VERSION "ev-fleet traction-motor 1.0"

NS_ :

BS_:

BU_: MotorFront MotorRear VCU

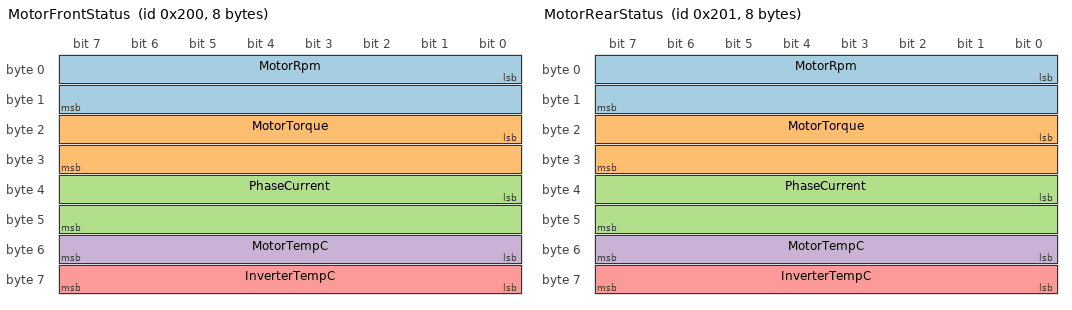
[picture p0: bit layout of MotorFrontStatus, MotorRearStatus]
BO_ 512 MotorFrontStatus: 8 MotorFront
 SG_ MotorRpm : 0|16@1- (1,0) [-32768|32767] "rpm" VCU
 SG_ MotorTorque : 16|16@1- (0.1,0) [-3276.8|3276.7] "Nm" VCU
 SG_ PhaseCurrent : 32|16@1- (0.1,0) [-3276.8|3276.7] "A" VCU
 SG_ MotorTempC : 48|8@1- (1,-40) [-40|87] "degC" VCU
 SG_ InverterTempC : 56|8@1- (1,-40) [-40|87] "degC" VCU

BO_ 513 MotorRearStatus: 8 MotorRear
 SG_ MotorRpm : 0|16@1- (1,0) [-32768|32767] "rpm" VCU
 SG_ MotorTorque : 16|16@1- (0.1,0) [-3276.8|3276.7] "Nm" VCU
 SG_ PhaseCurrent : 32|16@1- (0.1,0) [-3276.8|3276.7] "A" VCU
 SG_ MotorTempC : 48|8@1- (1,-40) [-40|87] "degC" VCU
 SG_ InverterTempC : 56|8@1- (1,-40) [-40|87] "degC" VCU

CM_ BO_ 512 "Front traction inverter status, 10 ms cadence on the powertrain bus. Reported to the VCU.";
CM_ BO_ 513 "Rear traction inverter status, 10 ms cadence on the powertrain bus. Reported to the VCU.";

BA_DEF_ BO_ "GenMsgCycleTime" INT 0 100000;
BA_DEF_DEF_ "GenMsgCycleTime" 0;
BA_ "GenMsgCycleTime" BO_ 512 10;
BA_ "GenMsgCycleTime" BO_ 513 10;
